# PY32MD410xx register map
Vendor: Puya; Series: PY32M; File version: 1.0.0
CPU: CM0+ r0p1, little endian, no MPU, no FPU, 4 interrupt priority bits
Registers are 32-bit, read-write, reset 0x0 unless marked. A register's access mark holds for its fields unless they carry their own. Offsets are from the block's base; [hi:lo] are bit positions; {n}, {i} and the like mark numbered series.

## GPIOA — General-purpose I/Os
Base 0x50000000
Same registers: GPIOB 0x50000400, GPIOF 0x50001400
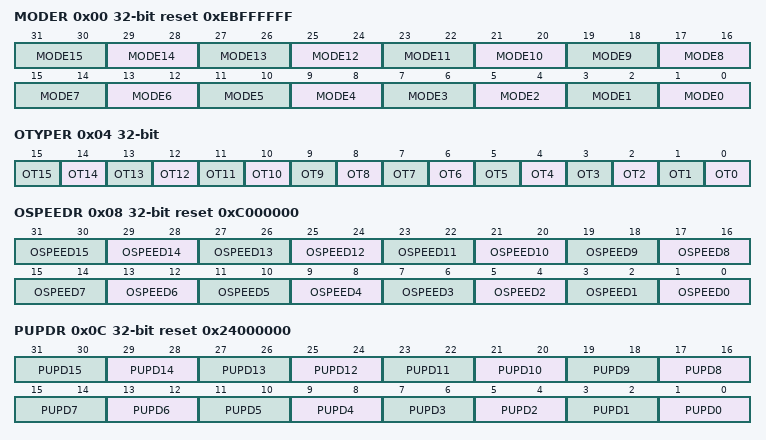
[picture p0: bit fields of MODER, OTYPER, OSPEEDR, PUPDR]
0x00 MODER reset 0xEBFFFFFF — GPIO port mode register
  [all] fields
    1=0; 2=1
  [2n+1:2n] MODE{n} (n=0..15) — Port x configuration bits (y = 0..15)
0x04 OTYPER — GPIO port output type register
  [n] OT{n} (n=0..15) — Port x configuration bits (y = 0..15)
0x08 OSPEEDR reset 0xC000000 — GPIO port output speed register
  [all] fields
    1=0; 2=1
  [2n+1:2n] OSPEED{n} (n=0..15) — Port x configuration bits (y = 0..15)
0x0C PUPDR reset 0x24000000 — GPIO port pull-up/pull-down register
  [all] fields
    1=0; 2=1
  [2n+1:2n] PUPD{n} (n=0..15) — Port x configuration bits (y = 0..15)
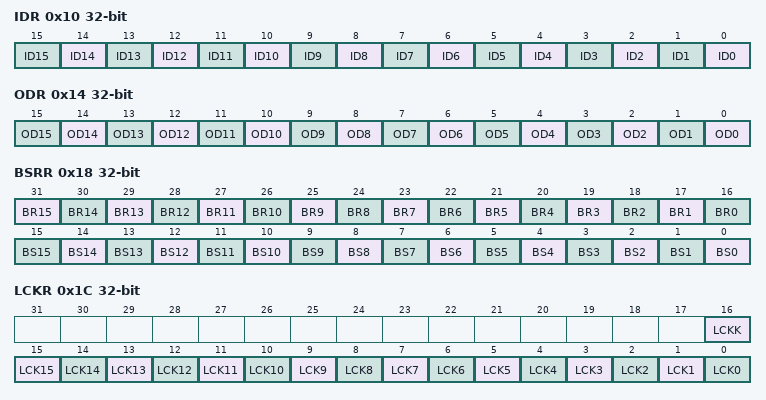
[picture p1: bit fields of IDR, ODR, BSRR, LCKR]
0x10 IDR ro — GPIO port input data register
  [n] ID{n} (n=0..15) — Port input data (y = 0..15)
0x14 ODR — GPIO port output data register
  [n] OD{n} (n=0..15) — Port output data (y = 0..15)
0x18 BSRR wo — GPIO port bit set/reset register
  [n+16] BR{n} (n=1..15) — Port x reset bit y (y = 0..15)
  [16] BR0 — Port x set bit y (y= 0..15)
  [n] BS{n} (n=0..15) — Port x set bit y (y= 0..15)
0x1C LCKR — GPIO port configuration lock register
  [16] LCKK — Port x lock bit y (y= 0..15)
  [n] LCK{n} (n=0..15) — Port x lock bit y (y= 0..15)
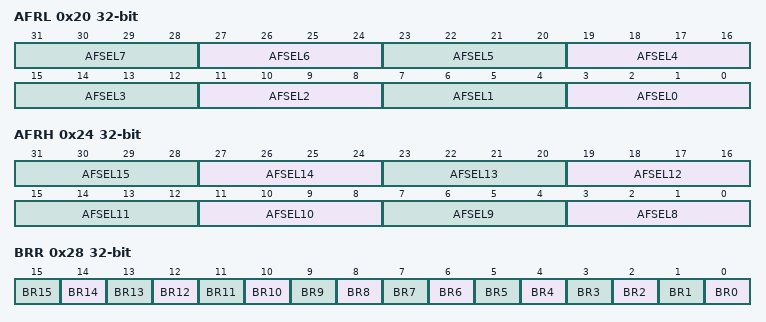
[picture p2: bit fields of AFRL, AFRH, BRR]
0x20 AFRL — GPIO alternate function low register
  [all] fields
    1=0; 2=1; 4=2; 8=3
  [4n+3:4n] AFSEL{n} (n=0..7) — Alternate function selection for port x bit y (y = 0..7)
0x24 AFRH — GPIO alternate function highregister
  [all] fields
    1=0; 2=1; 4=2; 8=3
  [4n-29:4n-32] AFSEL{n} (n=8..15) — Alternate function selection for port x bit y (y = 8..15)
0x28 BRR wo — port bit reset register
  [n] BR{n} (n=0..15) — Port Reset bit

## I2C1 — Inter integrated circuit
Base 0x40005400
Same registers: I2C2 0x40005800
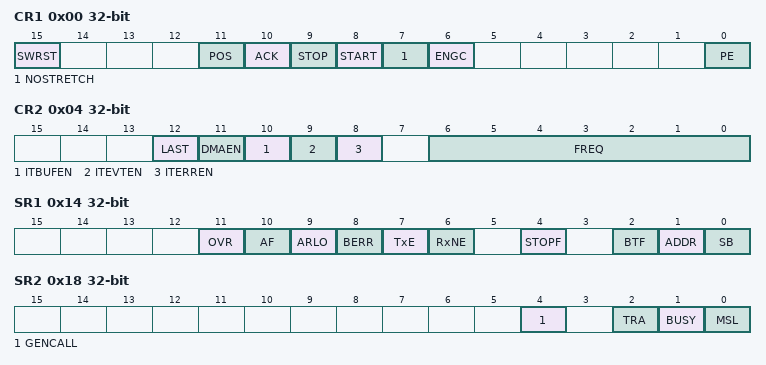
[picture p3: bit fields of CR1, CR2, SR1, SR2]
0x00 CR1 — Control register 1
  [15] SWRST — Software reset
  [11] POS — Acknowledge/PEC Position (for data reception)
  [10] ACK — Acknowledge enable
  [9] STOP — Stop generation
  [8] START — Start generation
  [7] NOSTRETCH — Clock stretching disable (Slave mode)
  [6] ENGC — General call enable
  [0] PE — Peripheral enable
0x04 CR2 — Control register 2
  [12] LAST — DMA last transfer
  [11] DMAEN — DMA requests enable
  [10] ITBUFEN — Buffer interrupt enable
  [9] ITEVTEN — Event interrupt enable
  [8] ITERREN — Error interrupt enable
  [6:0] FREQ — Peripheral clock frequency
    1=0; 2=1; 4=2; 8=3; 16=4; 32=5; 64=6
0x08 OAR1 — Own address register 1
  [7:1] ADD — Interface address
0x10 DR — Data register
  [7:0] DR — 8-bit data register
    1=0; 2=1; 4=2; 8=3; 16=4; 32=5; 64=6; 128=7
0x14 SR1 — Status register 1
  [11] OVR — Overrun/Underrun
  [10] AF — Acknowledge failure
  [9] ARLO — Arbitration lost (master mode)
  [8] BERR — Bus error
  [7] TxE ro — Data register empty (transmitters)
  [6] RxNE ro — Data register not empty (receivers)
  [4] STOPF ro — Stop detection (slave mode)
  [2] BTF ro — Byte transfer finished
  [1] ADDR ro — Address sent (master mode)/matched (slave mode)
  [0] SB ro — Start bit (Master mode)
0x18 SR2 ro — Status register 2
  [4] GENCALL — General call address (Slave mode)
  [2] TRA — Transmitter/receiver
  [1] BUSY — Bus busy
  [0] MSL — Master/slave
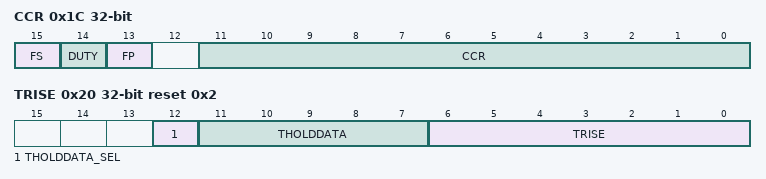
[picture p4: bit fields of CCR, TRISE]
0x1C CCR — Clock control register
  [15] FS — I2C master mode selection
  [14] DUTY — Fast mode duty cycle
  [13] FP — I2C master FP mode selection
  [11:0] CCR — Clock control register in Fast/Standard mode (Master mode)
0x20 TRISE reset 0x2
  [12] THOLDDATA_SEL
  [11:7] THOLDDATA
  [6:0] TRISE — Maximum rise time in Fast/Standard mode (Master mode)

## IWDG — Independent watchdog
Base 0x40003000
0x00 KR wo — Key register (IWDG_KR)
  [15:0] KEY — Key value
0x04 PR — Prescaler register (IWDG_PR)
  [2:0] PR — Prescaler divider
    1=0; 2=1; 4=2
0x08 RLR reset 0xFFF — Reload register (IWDG_RLR)
  [11:0] RL — Watchdog counter reload value
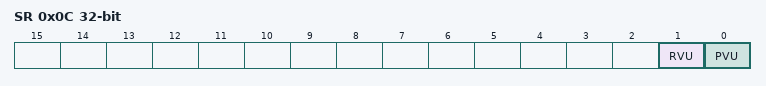
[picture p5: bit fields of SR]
0x0C SR ro — Status register (IWDG_SR)
  [1] RVU — Watchdog counter reload value update
  [0] PVU — Watchdog prescaler value update
